AUTOSAR XML (schema 4-2-2)
package /ComponentTypes
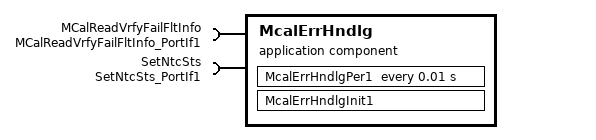
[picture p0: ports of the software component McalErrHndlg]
  application sw component type McalErrHndlg
    require port MCalReadVrfyFailFltInfo: client-com-spec=Oper, required-interface=MCalReadVrfyFailFltInfo_PortIf1
    require port SetNtcSts: client-com-spec=Oper, required-interface=SetNtcSts_PortIf1
    behavior McalErrHndlg_InternalBehavior
      ar-typed-per-instance-memorys:
        data CritErrCod: sw-calibration-access=READ-ONLY, type=uint8
        data NonCritErrCod: sw-calibration-access=READ-ONLY, type=uint8
      init event McalErrHndlg_InitEvent: start-on-event=McalErrHndlgInit1
      timing event TMT_McalErrHndlgPer1: start-on-event=McalErrHndlgPer1, period=0.01
      runnable McalErrHndlgInit1
        sync call SC_MCalReadVrfyFailFltInfo_Oper: operation=MCalReadVrfyFailFltInfo.Oper, timeout=0
        sync call SC_SetNtcSts_Oper: operation=SetNtcSts.Oper, timeout=0
      runnable McalErrHndlgPer1
        sync call SC_SetNtcSts_Oper: operation=SetNtcSts.Oper, timeout=0
  swc implementation McalErrHndlg_Implementation: behavior=McalErrHndlg_InternalBehavior
    code-descriptors:
      code Default: artifact-descriptors=autosar-engineering-object={short-label=Default, category=SWSRC}
